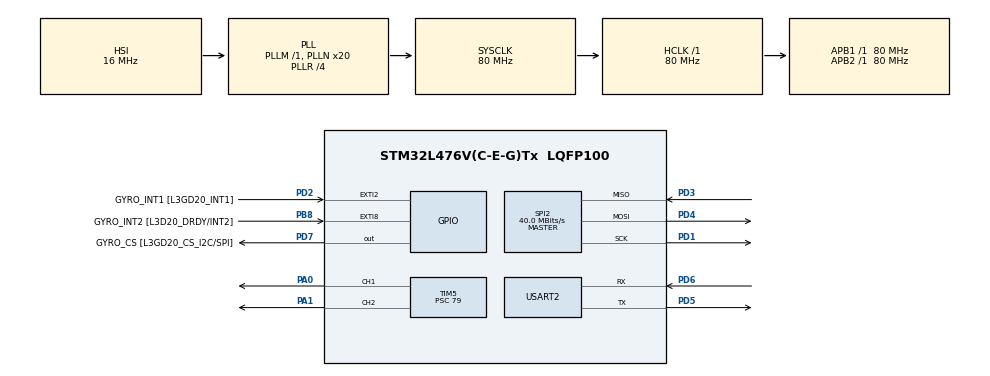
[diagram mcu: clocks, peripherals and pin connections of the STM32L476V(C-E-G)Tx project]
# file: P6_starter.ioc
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FREERTOS.Tasks01=defaultTask,0,128,StartDefaultTask,Default,NULL
FREERTOS.configTOTAL_HEAP_SIZE=10000
FREERTOS.configUSE_IDLE_HOOK=1
Mcu.Family=STM32L4
Mcu.Name=STM32L476V(C-E-G)Tx
Mcu.Package=LQFP100
NVIC.PriorityGroup=NVIC_PRIORITYGROUP_4
NVIC.TIM2_IRQn=true\:0\:0\:false\:false\:true\:false\:false
NVIC.TimeBase=TIM2_IRQn
NVIC.TimeBaseIP=TIM2
NVIC.USART2_IRQn=true\:5\:0\:false\:false\:true\:true\:true
PA0.GPIO_Speed=GPIO_SPEED_FREQ_HIGH
PA0.Signal=S_TIM5_CH1
PA1.GPIO_Speed=GPIO_SPEED_FREQ_HIGH
PA1.Signal=S_TIM5_CH2
PB8.GPIO_Label=GYRO_INT2 [L3D20_DRDY/INT2]
PB8.Signal=GPXTI8
PD1.Mode=Full_Duplex_Master
PD1.Signal=SPI2_SCK
PD2.GPIO_Label=GYRO_INT1 [L3GD20_INT1]
PD2.Signal=GPXTI2
PD3.Mode=Full_Duplex_Master
PD3.Signal=SPI2_MISO
PD4.Mode=Full_Duplex_Master
PD4.Signal=SPI2_MOSI
PD5.Mode=Asynchronous
PD5.Signal=USART2_TX
PD6.Mode=Asynchronous
PD6.Signal=USART2_RX
PD7.GPIO_Label=GYRO_CS [L3GD20_CS_I2C/SPI]
PD7.GPIO_Speed=GPIO_SPEED_FREQ_VERY_HIGH
PD7.Signal=GPIO_Output
ProjectManager.HeapSize=0x200
ProjectManager.StackSize=0x400
ProjectManager.TargetToolchain=MDK-ARM V5
RCC.ADCFreq_Value=96000000
RCC.AHBFreq_Value=80000000
RCC.APB1Freq_Value=80000000
RCC.APB1TimFreq_Value=80000000
RCC.APB2Freq_Value=80000000
RCC.APB2TimFreq_Value=80000000
RCC.CortexFreq_Value=80000000
RCC.HCLKFreq_Value=80000000
RCC.HSE_VALUE=8000000
RCC.HSI_VALUE=16000000
RCC.LSE_VALUE=32768
RCC.MSI_VALUE=4000000
RCC.PLLN=20
RCC.PLLR=RCC_PLLR_DIV4
RCC.PLLSAI1N=12
RCC.PLLSAI1Q=RCC_PLLQ_DIV4
RCC.PLLSourceVirtual=RCC_PLLSOURCE_HSI
RCC.SYSCLKFreq_VALUE=80000000
RCC.SYSCLKSource=RCC_SYSCLKSOURCE_PLLCLK
RCC.USBFreq_Value=48000000
RCC.VCOOutputFreq_Value=320000000
SH.S_TIM5_CH1.0=TIM5_CH1,PWM Generation1 CH1
SH.S_TIM5_CH2.0=TIM5_CH2,PWM Generation2 CH2
SPI2.CalculateBaudRate=40.0 MBits/s
SPI2.Direction=SPI_DIRECTION_2LINES
SPI2.Mode=SPI_MODE_MASTER
SPI2.VirtualType=VM_MASTER
TIM5.Channel-PWM\ Generation1\ CH1=TIM_CHANNEL_1
TIM5.Channel-PWM\ Generation2\ CH2=TIM_CHANNEL_2
TIM5.Period=20000
TIM5.Prescaler=79
TIM5.Pulse-PWM\ Generation1\ CH1=10000
TIM5.Pulse-PWM\ Generation2\ CH2=1000
USART2.VirtualMode-Asynchronous=VM_ASYNC
VP_FREERTOS_VS_ENABLE.Mode=Enabled
VP_RNG_VS_RNG.Mode=RNG_Activate
VP_SYS_VS_tim2.Mode=TIM2
VP_TIM5_VS_ClockSourceINT.Mode=Internal
board=custom

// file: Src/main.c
/* USER CODE BEGIN Header */
/**
  ******************************************************************************
  * @file           : main.c
  * @brief          : Main program body
  ******************************************************************************
  * This notice applies to any and all portions of this file
  * that are not between comment pairs USER CODE BEGIN and
  * USER CODE END. Other portions of this file, whether
  * inserted by the user or by software development tools
  * are owned by their respective copyright owners.
  *
  * Copyright (c) 2019 STMicroelectronics International N.V.
  * All rights reserved.
  *
  * Redistribution and use in source and binary forms, with or without
  * modification, are permitted, provided that the following conditions are met:
  *
  * 1. Redistribution of source code must retain the above copyright notice,
  *    this list of conditions and the following disclaimer.
  * 2. Redistributions in binary form must reproduce the above copyright notice,
  *    this list of conditions and the following disclaimer in the documentation
  *    and/or other materials provided with the distribution.
  * 3. Neither the name of STMicroelectronics nor the names of other
  *    contributors to this software may be used to endorse or promote products
  *    derived from this software without specific written permission.
  * 4. This software, including modifications and/or derivative works of this
  *    software, must execute solely and exclusively on microcontroller or
  *    microprocessor devices manufactured by or for STMicroelectronics.
  * 5. Redistribution and use of this software other than as permitted under
  *    this license is void and will automatically terminate your rights under
  *    this license.
  *
  * THIS SOFTWARE IS PROVIDED BY STMICROELECTRONICS AND CONTRIBUTORS "AS IS"
  * AND ANY EXPRESS, IMPLIED OR STATUTORY WARRANTIES, INCLUDING, BUT NOT
  * LIMITED TO, THE IMPLIED WARRANTIES OF MERCHANTABILITY, FITNESS FOR A
  * PARTICULAR PURPOSE AND NON-INFRINGEMENT OF THIRD PARTY INTELLECTUAL PROPERTY
  * RIGHTS ARE DISCLAIMED TO THE FULLEST EXTENT PERMITTED BY LAW. IN NO EVENT
  * SHALL STMICROELECTRONICS OR CONTRIBUTORS BE LIABLE FOR ANY DIRECT, INDIRECT,
  * INCIDENTAL, SPECIAL, EXEMPLARY, OR CONSEQUENTIAL DAMAGES (INCLUDING, BUT NOT
  * LIMITED TO, PROCUREMENT OF SUBSTITUTE GOODS OR SERVICES; LOSS OF USE, DATA,
  * OR PROFITS; OR BUSINESS INTERRUPTION) HOWEVER CAUSED AND ON ANY THEORY OF
  * LIABILITY, WHETHER IN CONTRACT, STRICT LIABILITY, OR TORT (INCLUDING
  * NEGLIGENCE OR OTHERWISE) ARISING IN ANY WAY OUT OF THE USE OF THIS SOFTWARE,
  * EVEN IF ADVISED OF THE POSSIBILITY OF SUCH DAMAGE.
  *
  ******************************************************************************
  */
/* USER CODE END Header */

#include "main.h"
#include "cmsis_os.h"

/* USER CODE BEGIN Includes */
#include "stdio.h"
#include "string.h"
/* USER CODE END Includes */

RNG_HandleTypeDef hrng;

SPI_HandleTypeDef hspi2;

TIM_HandleTypeDef htim5;

UART_HandleTypeDef huart2;

osThreadId defaultTaskHandle;
/* USER CODE BEGIN PV */
SemaphoreHandle_t servo1_mutex, servo2_mutex;
uint8_t  servo1_position;
uint8_t  servo2_position;

/* USER CODE END PV */

void SystemClock_Config(void);
static void MX_GPIO_Init(void);
static void MX_USART2_UART_Init(void);
static void MX_RNG_Init(void);
static void MX_TIM5_Init(void);
static void MX_SPI2_Init(void);
void StartDefaultTask(void const * argument);

/* USER CODE END 0 */

int main(void)
{

  /* MCU Configuration--------------------------------------------------------*/

  /* Reset of all peripherals, Initializes the Flash interface and the Systick. */
  HAL_Init();

  /* Configure the system clock */
  SystemClock_Config();

  /* Initialize all configured peripherals */
  MX_GPIO_Init();
  MX_USART2_UART_Init();
  MX_RNG_Init();
  MX_TIM5_Init();
  MX_SPI2_Init();

  /* USER CODE BEGIN RTOS_MUTEX */
  servo1_mutex = xSemaphoreCreateMutex();
  servo2_mutex = xSemaphoreCreateMutex();
  /* USER CODE END RTOS_MUTEX */

  /* Create the thread(s) */
  /* definition and creation of defaultTask */
  osThreadDef(defaultTask, StartDefaultTask, osPriorityNormal, 0, 128);
  defaultTaskHandle = osThreadCreate(osThread(defaultTask), NULL);

  /* USER CODE BEGIN RTOS_THREADS */
  /* add threads, ... */
  print_task_init();
  pwm_task_init();
  gyro_task_init();
  referee_task_init();

  /* USER CODE END RTOS_THREADS */

  /* Start scheduler */
  osKernelStart();

  /* We should never get here as control is now taken by the scheduler */

  /* Infinite loop */
  while (1)
  {

  }
}

void SystemClock_Config(void)
{
  RCC_OscInitTypeDef RCC_OscInitStruct = {0};
  RCC_ClkInitTypeDef RCC_ClkInitStruct = {0};
  RCC_PeriphCLKInitTypeDef PeriphClkInit = {0};

  /**Initializes the CPU, AHB and APB busses clocks
  */
  RCC_OscInitStruct.OscillatorType = RCC_OSCILLATORTYPE_HSI;
  RCC_OscInitStruct.HSIState = RCC_HSI_ON;
  RCC_OscInitStruct.HSICalibrationValue = RCC_HSICALIBRATION_DEFAULT;
  RCC_OscInitStruct.PLL.PLLState = RCC_PLL_ON;
  RCC_OscInitStruct.PLL.PLLSource = RCC_PLLSOURCE_HSI;
  RCC_OscInitStruct.PLL.PLLM = 1;
  RCC_OscInitStruct.PLL.PLLN = 20;
  RCC_OscInitStruct.PLL.PLLP = RCC_PLLP_DIV7;
  RCC_OscInitStruct.PLL.PLLQ = RCC_PLLQ_DIV2;
  RCC_OscInitStruct.PLL.PLLR = RCC_PLLR_DIV4;
  if (HAL_RCC_OscConfig(&RCC_OscInitStruct) != HAL_OK)
  {
    Error_Handler();
  }
  /**Initializes the CPU, AHB and APB busses clocks
  */
  RCC_ClkInitStruct.ClockType = RCC_CLOCKTYPE_HCLK|RCC_CLOCKTYPE_SYSCLK
                              |RCC_CLOCKTYPE_PCLK1|RCC_CLOCKTYPE_PCLK2;
  RCC_ClkInitStruct.SYSCLKSource = RCC_SYSCLKSOURCE_PLLCLK;
  RCC_ClkInitStruct.AHBCLKDivider = RCC_SYSCLK_DIV1;
  RCC_ClkInitStruct.APB1CLKDivider = RCC_HCLK_DIV1;
  RCC_ClkInitStruct.APB2CLKDivider = RCC_HCLK_DIV1;

  if (HAL_RCC_ClockConfig(&RCC_ClkInitStruct, FLASH_LATENCY_4) != HAL_OK)
  {
    Error_Handler();
  }
  PeriphClkInit.PeriphClockSelection = RCC_PERIPHCLK_USART2|RCC_PERIPHCLK_RNG;
  PeriphClkInit.Usart2ClockSelection = RCC_USART2CLKSOURCE_PCLK1;
  PeriphClkInit.RngClockSelection = RCC_RNGCLKSOURCE_PLLSAI1;
  PeriphClkInit.PLLSAI1.PLLSAI1Source = RCC_PLLSOURCE_HSI;
  PeriphClkInit.PLLSAI1.PLLSAI1M = 1;
  PeriphClkInit.PLLSAI1.PLLSAI1N = 12;
  PeriphClkInit.PLLSAI1.PLLSAI1P = RCC_PLLP_DIV7;
  PeriphClkInit.PLLSAI1.PLLSAI1Q = RCC_PLLQ_DIV4;
  PeriphClkInit.PLLSAI1.PLLSAI1R = RCC_PLLR_DIV2;
  PeriphClkInit.PLLSAI1.PLLSAI1ClockOut = RCC_PLLSAI1_48M2CLK;
  if (HAL_RCCEx_PeriphCLKConfig(&PeriphClkInit) != HAL_OK)
  {
    Error_Handler();
  }
  /**Configure the main internal regulator output voltage
  */
  if (HAL_PWREx_ControlVoltageScaling(PWR_REGULATOR_VOLTAGE_SCALE1) != HAL_OK)
  {
    Error_Handler();
  }
}

static void MX_RNG_Init(void)
{

  hrng.Instance = RNG;
  if (HAL_RNG_Init(&hrng) != HAL_OK)
  {
    Error_Handler();
  }

}

static void MX_SPI2_Init(void)
{

  /* SPI2 parameter configuration*/
  hspi2.Instance = SPI2;
  hspi2.Init.Mode = SPI_MODE_MASTER;
  hspi2.Init.Direction = SPI_DIRECTION_2LINES;
  hspi2.Init.DataSize = SPI_DATASIZE_4BIT;
  hspi2.Init.CLKPolarity = SPI_POLARITY_LOW;
  hspi2.Init.CLKPhase = SPI_PHASE_1EDGE;
  hspi2.Init.NSS = SPI_NSS_SOFT;
  hspi2.Init.BaudRatePrescaler = SPI_BAUDRATEPRESCALER_2;
  hspi2.Init.FirstBit = SPI_FIRSTBIT_MSB;
  hspi2.Init.TIMode = SPI_TIMODE_DISABLE;
  hspi2.Init.CRCCalculation = SPI_CRCCALCULATION_DISABLE;
  hspi2.Init.CRCPolynomial = 7;
  hspi2.Init.CRCLength = SPI_CRC_LENGTH_DATASIZE;
  hspi2.Init.NSSPMode = SPI_NSS_PULSE_ENABLE;
  if (HAL_SPI_Init(&hspi2) != HAL_OK)
  {
    Error_Handler();
  }

}

static void MX_TIM5_Init(void)
{

  TIM_ClockConfigTypeDef sClockSourceConfig = {0};
  TIM_MasterConfigTypeDef sMasterConfig = {0};
  TIM_OC_InitTypeDef sConfigOC = {0};

  htim5.Instance = TIM5;
  htim5.Init.Prescaler = 79;
  htim5.Init.CounterMode = TIM_COUNTERMODE_UP;
  htim5.Init.Period = 20000;
  htim5.Init.ClockDivision = TIM_CLOCKDIVISION_DIV1;
  htim5.Init.AutoReloadPreload = TIM_AUTORELOAD_PRELOAD_DISABLE;
  if (HAL_TIM_Base_Init(&htim5) != HAL_OK)
  {
    Error_Handler();
  }
  sClockSourceConfig.ClockSource = TIM_CLOCKSOURCE_INTERNAL;
  if (HAL_TIM_ConfigClockSource(&htim5, &sClockSourceConfig) != HAL_OK)
  {
    Error_Handler();
  }
  if (HAL_TIM_PWM_Init(&htim5) != HAL_OK)
  {
    Error_Handler();
  }
  sMasterConfig.MasterOutputTrigger = TIM_TRGO_RESET;
  sMasterConfig.MasterSlaveMode = TIM_MASTERSLAVEMODE_DISABLE;
  if (HAL_TIMEx_MasterConfigSynchronization(&htim5, &sMasterConfig) != HAL_OK)
  {
    Error_Handler();
  }
  sConfigOC.OCMode = TIM_OCMODE_PWM1;
  sConfigOC.Pulse = 10000;
  sConfigOC.OCPolarity = TIM_OCPOLARITY_HIGH;
  sConfigOC.OCFastMode = TIM_OCFAST_DISABLE;
  if (HAL_TIM_PWM_ConfigChannel(&htim5, &sConfigOC, TIM_CHANNEL_1) != HAL_OK)
  {
    Error_Handler();
  }
  sConfigOC.Pulse = 1000;
  if (HAL_TIM_PWM_ConfigChannel(&htim5, &sConfigOC, TIM_CHANNEL_2) != HAL_OK)
  {
    Error_Handler();
  }
  HAL_TIM_MspPostInit(&htim5);

}

static void MX_USART2_UART_Init(void)
{

  huart2.Instance = USART2;
  huart2.Init.BaudRate = 115200;
  huart2.Init.WordLength = UART_WORDLENGTH_8B;
  huart2.Init.StopBits = UART_STOPBITS_1;
  huart2.Init.Parity = UART_PARITY_NONE;
  huart2.Init.Mode = UART_MODE_TX_RX;
  huart2.Init.HwFlowCtl = UART_HWCONTROL_NONE;
  huart2.Init.OverSampling = UART_OVERSAMPLING_16;
  huart2.Init.OneBitSampling = UART_ONE_BIT_SAMPLE_DISABLE;
  huart2.AdvancedInit.AdvFeatureInit = UART_ADVFEATURE_NO_INIT;
  if (HAL_UART_Init(&huart2) != HAL_OK)
  {
    Error_Handler();
  }

}

static void MX_GPIO_Init(void)
{
  GPIO_InitTypeDef GPIO_InitStruct = {0};

  /* GPIO Ports Clock Enable */
  __HAL_RCC_GPIOA_CLK_ENABLE();
  __HAL_RCC_GPIOD_CLK_ENABLE();
  __HAL_RCC_GPIOB_CLK_ENABLE();

  /*Configure GPIO pin Output Level */
  HAL_GPIO_WritePin(GYRO_CS_GPIO_Port, GYRO_CS_Pin, GPIO_PIN_RESET);

  /*Configure GPIO pin : GYRO_INT1_Pin */
  GPIO_InitStruct.Pin = GYRO_INT1_Pin;
  GPIO_InitStruct.Mode = GPIO_MODE_IT_RISING;
  GPIO_InitStruct.Pull = GPIO_NOPULL;
  HAL_GPIO_Init(GYRO_INT1_GPIO_Port, &GPIO_InitStruct);

  /*Configure GPIO pin : GYRO_CS_Pin */
  GPIO_InitStruct.Pin = GYRO_CS_Pin;
  GPIO_InitStruct.Mode = GPIO_MODE_OUTPUT_PP;
  GPIO_InitStruct.Pull = GPIO_NOPULL;
  GPIO_InitStruct.Speed = GPIO_SPEED_FREQ_VERY_HIGH;
  HAL_GPIO_Init(GYRO_CS_GPIO_Port, &GPIO_InitStruct);

  /*Configure GPIO pin : GYRO_INT2_Pin */
  GPIO_InitStruct.Pin = GYRO_INT2_Pin;
  GPIO_InitStruct.Mode = GPIO_MODE_IT_RISING;
  GPIO_InitStruct.Pull = GPIO_NOPULL;
  HAL_GPIO_Init(GYRO_INT2_GPIO_Port, &GPIO_InitStruct);

}

void StartDefaultTask(void const * argument)
{

  for(;;)
  {
    osDelay(1);
  }
}

void HAL_TIM_PeriodElapsedCallback(TIM_HandleTypeDef *htim)
{
  if (htim->Instance == TIM2) {
    HAL_IncTick();
  }
}

void Error_Handler(void)
{
}

/************************ (C) COPYRIGHT STMicroelectronics *****END OF FILE****/
